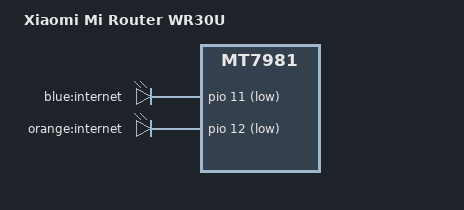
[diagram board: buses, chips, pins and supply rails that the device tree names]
// SPDX-License-Identifier: GPL-2.0-or-later OR MIT

/dts-v1/;

#include "mt7981b-xiaomi_mi-router.dtsi"

/ {
	model = "Xiaomi Mi Router WR30U";
	compatible = "xiaomi,mi-router-wr30u", "mediatek,mt7981";
};

&gmac0 {
	nvmem-cell-names = "mac-address";
	nvmem-cells = <&macaddr_factory_4 (-1)>;
};

&leds {
	internet_blue {
		label = "blue:internet";
		gpios = <&pio 11 GPIO_ACTIVE_LOW>;
	};

	internet_orange {
		label = "orange:internet";
		gpios = <&pio 12 GPIO_ACTIVE_LOW>;
	};
};
